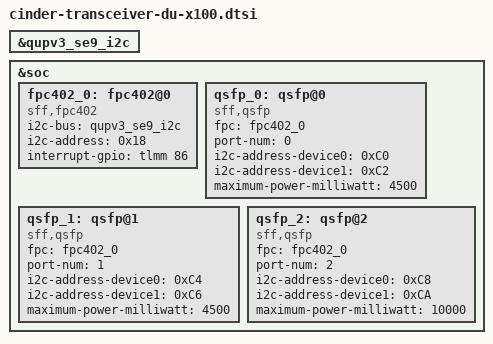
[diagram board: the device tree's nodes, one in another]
&qupv3_se9_i2c {
	status = "ok";
};

&soc {
	fpc402_0: fpc402@0 {
		compatible = "sff,fpc402";
		i2c-bus = <&qupv3_se9_i2c>;
		i2c-address = <0x18>;
		interrupt-gpio = <&tlmm 86 0>;
	};

	qsfp_0: qsfp@0 {
		compatible = "sff,qsfp";
		fpc = <&fpc402_0>;
		port-num = <0>;
		i2c-address-device0 = <0xC0>;
		i2c-address-device1 = <0xC2>;
		maximum-power-milliwatt = <4500>;
	};

	qsfp_1: qsfp@1 {
		compatible = "sff,qsfp";
		fpc = <&fpc402_0>;
		port-num = <1>;
		i2c-address-device0 = <0xC4>;
		i2c-address-device1 = <0xC6>;
		maximum-power-milliwatt = <4500>;
	};

	qsfp_2: qsfp@2 {
		compatible = "sff,qsfp";
		fpc = <&fpc402_0>;
		port-num = <2>;
		i2c-address-device0 = <0xC8>;
		i2c-address-device1 = <0xCA>;
                // qsfp-dd port max power is 10W
		maximum-power-milliwatt = <10000>;
	};
};
